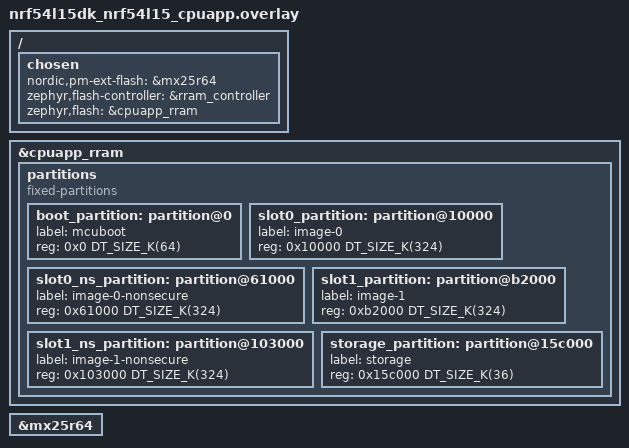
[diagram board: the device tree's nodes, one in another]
/*
 * Copyright (c) 2024 Nordic Semiconductor ASA
 *
 * SPDX-License-Identifier: LicenseRef-Nordic-5-Clause
 */

/ {
	chosen {
		nordic,pm-ext-flash = &mx25r64;
		zephyr,flash-controller = &rram_controller;
		zephyr,flash = &cpuapp_rram;
	};
};

// restore full RRAM and SRAM space - by default some parts are dedicated to FLRP
&cpuapp_rram {
	/delete-node/ partitions;

	partitions {
		compatible = "fixed-partitions";
		#address-cells = <1>;
		#size-cells = <1>;
		boot_partition: partition@0 {
			label = "mcuboot";
			reg = <0x0 DT_SIZE_K(64)>;
		};
		slot0_partition: partition@10000 {
			label = "image-0";
			reg = <0x10000 DT_SIZE_K(324)>;
		};
		slot0_ns_partition: partition@61000 {
			label = "image-0-nonsecure";
			reg = <0x61000 DT_SIZE_K(324)>;
		};
		slot1_partition: partition@b2000 {
			label = "image-1";
			reg = <0xb2000 DT_SIZE_K(324)>;
		};
		slot1_ns_partition: partition@103000 {
			label = "image-1-nonsecure";
			reg = <0x103000 DT_SIZE_K(324)>;
		};
		/* 32k from 0x154000 to 0x15bfff reserved for TF-M partitions */
		storage_partition: partition@15c000 {
			label = "storage";
			reg = <0x15c000 DT_SIZE_K(36)>;
		};
	};
};

&mx25r64 {
	status = "okay";
};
